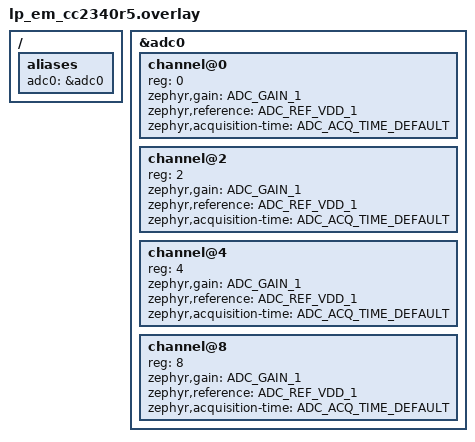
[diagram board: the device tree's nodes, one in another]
/*
 * Copyright (c) 2024 BayLibre, SAS
 *
 * SPDX-License-Identifier: Apache-2.0
 */

#include <zephyr/dt-bindings/adc/adc.h>

/ {
	aliases {
		adc0 = &adc0;
	};
};

&adc0 {
	status = "okay";

	#address-cells = <1>;
	#size-cells = <0>;

	channel@0 {
		reg = <0>;
		zephyr,gain = "ADC_GAIN_1";
		zephyr,reference = "ADC_REF_VDD_1";
		zephyr,acquisition-time = <ADC_ACQ_TIME_DEFAULT>;
	};

	channel@2 {
		reg = <2>;
		zephyr,gain = "ADC_GAIN_1";
		zephyr,reference = "ADC_REF_VDD_1";
		zephyr,acquisition-time = <ADC_ACQ_TIME_DEFAULT>;
	};

	channel@4 {
		reg = <4>;
		zephyr,gain = "ADC_GAIN_1";
		zephyr,reference = "ADC_REF_VDD_1";
		zephyr,acquisition-time = <ADC_ACQ_TIME_DEFAULT>;
	};

	channel@8 {
		reg = <8>;
		zephyr,gain = "ADC_GAIN_1";
		zephyr,reference = "ADC_REF_VDD_1";
		zephyr,acquisition-time = <ADC_ACQ_TIME_DEFAULT>;
	};
};
